AUTOSAR XML (schema 4-3-0)
standard types defined: boolean, float32, sint32, boolean_CompuMethod, boolean_DataConstr, float32_DataConstr, sint32_DataConstr, uint8, sint16, uint16
package /ASP_DataTypes
  8 x impl type:
    As_FeatureOutput: category=STRUCTURE
      element Status: implementation-data-type=As_Status  # Information if feature is available
      element Available: implementation-data-type=As_SideAvailable  # Feature side dependent availability
      element WarningSide: implementation-data-type=As_Side  # Trigger warning for the feature
    As_FrontWheelRequest: category=STRUCTURE
      6 x element, all with category=TYPE_REFERENCE, implementation-data-type=float32:
        Angle  # Wheel angle request
        AngleRateLimit  # The front wheel angle rate limit
        LowerTorqueLimit  # Minimum value for function applied torque, defined at the steering column
        UpperLorqueLimit  # Maximum value for function applied torque, defined at the steering column
        AdditionalTorque  # The signal can be interpreted as a feed forward signal
        BandwidthScaling  # The desired bandwidth for the angle controller ranges from 0 (minimum bandwidth) to 1 (maximum bandwidth)
    As_LateralControlMode: compu {0=As_NoRequest, 1=As_TrafficAssist, 2=As_Lka, 3=As_ElkaRoadEdge, 4=As_ElkaFrontObjects, 5=As_ElkaBlis}, implementation-data-type=sint32
    As_LateralControlOutput: category=STRUCTURE
      element Mode: implementation-data-type=As_LateralControlMode  # Requested lateral actuation mode
      element FrontWheelRequest: implementation-data-type=As_FrontWheelRequest  # Requested front wheel actuation
    As_LssOutput: category=STRUCTURE
      6 x element, all with category=TYPE_REFERENCE:
        Ldw: implementation-data-type=As_FeatureOutput  # Feature output for LDW function
        Lka: implementation-data-type=As_FeatureOutput  # Feature output for LKA function
        ElkaRoadEdge: implementation-data-type=As_FeatureOutput  # Feature output for eLKA Road Edge function
        ElkaFrontObjects: implementation-data-type=As_FeatureOutput  # Feature output for eLKA Front Objects function (e.g. oncoming)
        ElkaRearObjects: implementation-data-type=As_FeatureOutput  # Feature output for eLKA Rear Objects function (e.g. Blind Spot)
        RequestPostEventMessage: implementation-data-type=boolean  # Post event message request
    As_Side: compu {0=As_None, 1=As_Left, 2=As_Right, 3=As_LeftAndRight}, implementation-data-type=sint32
    As_SideAvailable: category=STRUCTURE
      element Left: implementation-data-type=boolean  # Available left side
      element Right: implementation-data-type=boolean  # Available right side
    As_Status: compu {0=As_Disabled, 1=As_Unavailable, 2=As_Available}, implementation-data-type=sint32
package /ASP_PortInterfaces
  sender receiver interface LateralControlOutputInterface: invalidation-policy{data-element=LateralControlOutputInterface/Element, handle-invalid=DONT-INVALIDATE}
    data Element: type=As_LateralControlOutput
  sender receiver interface LssOutputInterface: invalidation-policy{data-element=LssOutputInterface/Element, handle-invalid=DONT-INVALIDATE}
    data Element: type=As_LssOutput
package /ComponentTypes/HkmcComponent/HkmcLkaLdwAdap
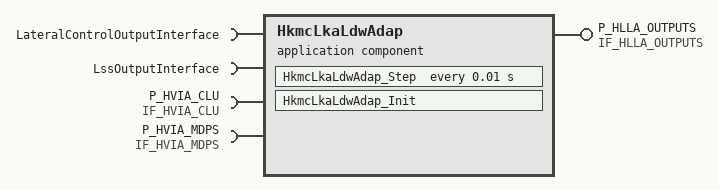
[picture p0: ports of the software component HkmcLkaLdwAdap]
  application sw component type HkmcLkaLdwAdap
    provide port P_HLLA_OUTPUTS: nonqueued-sender-com-spec{data-element=DE_HLLA_OUTPUTS, init-value=fields=[LkaAdap_OptUsmSta:0, LkaAdap_ToiFltSta:0, LkaAdap_ActToiSta:0, LkaAdap_StrTrqReqVal:0, LkaAdap_RHLnWrnSta:0, LkaAdap_LHLnWrnSta:0, LkaAdap_SysWrn:0, LkaAdap_RcgSta:0, LkaAdap_HndsoffSnd:0, LkaAdap_UsmMod:0, LkaAdap_SysIndReq:0, LkaAdap_leftLaneLateral_distance:0, LkaAdap_rightLaneLateral_distance:0, LkaAdap_leftLaneheading:0, LkaAdap_rightLaneheading:0, LkaAdap_leftLanecurvature:0, LkaAdap_leftLanecurvature_rate:0, LkaAdap_rightLanecurvature_rate:0, LkaAdap_leftLaneDetection_distance:0, LkaAdap_rightLaneDetection_distance:0, LkaAdap_lane_right_color:0, LkaAdap_lane_left_color:0, LkaAdap_leftLanemeasurement_quality:0, LkaAdap_rightLanemeasurement_quality:0, LkaAdap_leftLanemarkingtype:0, LkaAdap_rightLanemarkingtype:0, LkaAdap_neighborleftLaneLateral_distance:0, LkaAdap_neighborrightLaneLateral_distance:0, LkaAdap_neighborleftLaneheading:0, LkaAdap_neighborrightLaneheading:0, LkaAdap_neighborleftLanecurvature:0, LkaAdap_neighborrightLanecurvature:0, LkaAdap_neighborleftLanecurvature_rate:0, LkaAdap_neighborrightLanecurvature_rate:0, LkaAdap_neighborleftmeasurement_quality:0, LkaAdap_neighborrightmeasurement_quality:0, LkaAdap_neighborleftLanemarkingtype:0, LkaAdap_neighborrightLanemarkingtype:0]}, provided-interface=IF_HLLA_OUTPUTS
    4 x require port:
      LateralControlOutputInterface: nonqueued-receiver-com-spec{data-element=LateralControlOutputInterface/Element, filter=data-filter-type=ALWAYS}, required-interface=LateralControlOutputInterface
      LssOutputInterface: nonqueued-receiver-com-spec{data-element=LssOutputInterface/Element, filter=data-filter-type=ALWAYS}, required-interface=LssOutputInterface
      P_HVIA_CLU: nonqueued-receiver-com-spec{data-element=DE_HVIA_CLU, filter=data-filter-type=ALWAYS, init-value=fields=[HkmcVehicleInput_SpdUnitTyp:0, HkmcVehicleInput_Fca1stWrngSetReq:0, HkmcVehicleInput_AdasFCASetReq:0, HkmcVehicleInput_LkaModSetReq:0, HkmcVehInput_HBA_NValueSet:0, HkmcVehicleInput_AdasISLASetReq:0]}, required-interface=IF_HVIA_CLU
      P_HVIA_MDPS: nonqueued-receiver-com-spec{data-element=DE_HVIA_MDPS, filter=data-filter-type=ALWAYS, init-value=fields=HkmcVehicleInput_LkaToiUnblSta:0}, required-interface=IF_HVIA_MDPS
    behavior HkmcLkaLdwAdap_InternalBehavior
      init event HkmcLkaLdwAdap_InitEvent: start-on-event=HkmcLkaLdwAdap_Init
      timing event HkmcLkaLdwAdap_Step_TE: start-on-event=HkmcLkaLdwAdap_Step, period=0.01
      runnable HkmcLkaLdwAdap_Init
        data-receive-point-by-arguments:
          4 x access:
            REC_LateralControlOutputInterface_Element: accessed-variable=LateralControlOutputInterface.Element
            REC_LssOutputInterface_Element: accessed-variable=LssOutputInterface.Element
            REC_P_HVIA_CLU_DE_HVIA_CLU: accessed-variable=P_HVIA_CLU.DE_HVIA_CLU
            REC_P_HVIA_MDPS_DE_HVIA_MDPS: accessed-variable=P_HVIA_MDPS.DE_HVIA_MDPS
        data-send-points:
          access SEND_P_HLLA_OUTPUTS_DE_HLLA_OUTPUTS: accessed-variable=P_HLLA_OUTPUTS.DE_HLLA_OUTPUTS
      runnable HkmcLkaLdwAdap_Step
        data-receive-point-by-arguments:
          4 x access:
            REC_LateralControlOutputInterface_Element: accessed-variable=LateralControlOutputInterface.Element
            REC_LssOutputInterface_Element: accessed-variable=LssOutputInterface.Element
            REC_P_HVIA_CLU_DE_HVIA_CLU: accessed-variable=P_HVIA_CLU.DE_HVIA_CLU
            REC_P_HVIA_MDPS_DE_HVIA_MDPS: accessed-variable=P_HVIA_MDPS.DE_HVIA_MDPS
        data-send-points:
          access SEND_P_HLLA_OUTPUTS_DE_HLLA_OUTPUTS: accessed-variable=P_HLLA_OUTPUTS.DE_HLLA_OUTPUTS
  swc implementation HkmcLkaLdwAdap_Implementation: behavior=HkmcLkaLdwAdap_InternalBehavior
    code-descriptors:
      code Default: artifact-descriptors=autosar-engineering-object={short-label=Default, category=SWSRC}
package /ComponentTypes/HkmcComponent/HkmcLkaLdwAdap/DataTypes
  39 x impl type, all with sw-calibration-access=READ-ONLY, type-emitter=RTE:
    HLLA_OUTPUTS_T: category=STRUCTURE
      38 x element, all with category=TYPE_REFERENCE:
        LkaAdap_OptUsmSta: implementation-data-type=LkaAdap_OptUsmSta
        LkaAdap_ToiFltSta: implementation-data-type=LkaAdap_ToiFltSta
        LkaAdap_ActToiSta: implementation-data-type=LkaAdap_ActToiSta
        LkaAdap_StrTrqReqVal: implementation-data-type=LkaAdap_StrTrqReqVal
        LkaAdap_RHLnWrnSta: implementation-data-type=LkaAdap_RHLnWrnSta
        LkaAdap_LHLnWrnSta: implementation-data-type=LkaAdap_LHLnWrnSta
        LkaAdap_SysWrn: implementation-data-type=LkaAdap_SysWrn
        LkaAdap_RcgSta: implementation-data-type=LkaAdap_RcgSta
        LkaAdap_HndsoffSnd: implementation-data-type=LkaAdap_HndsoffSnd
        LkaAdap_UsmMod: implementation-data-type=LkaAdap_UsmMod
        LkaAdap_SysIndReq: implementation-data-type=LkaAdap_SysIndReq
        LkaAdap_leftLaneLateral_distance: implementation-data-type=LkaAdap_leftLaneLateral_distance
        LkaAdap_rightLaneLateral_distance: implementation-data-type=LkaAdap_rightLaneLateral_distance
        LkaAdap_leftLaneheading: implementation-data-type=LkaAdap_leftLaneheading
        LkaAdap_rightLaneheading: implementation-data-type=LkaAdap_rightLaneheading
        LkaAdap_leftLanecurvature: implementation-data-type=LkaAdap_leftLanecurvature
        LkaAdap_leftLanecurvature_rate: implementation-data-type=LkaAdap_leftLanecurvature_rate
        LkaAdap_rightLanecurvature_rate: implementation-data-type=LkaAdap_rightLanecurvature_rate
        LkaAdap_leftLaneDetection_distance: implementation-data-type=LkaAdap_leftLaneDetection_distance
        LkaAdap_rightLaneDetection_distance: implementation-data-type=LkaAdap_rightLaneDetection_distance
        LkaAdap_lane_right_color: implementation-data-type=LkaAdap_lane_right_color
        LkaAdap_lane_left_color: implementation-data-type=LkaAdap_lane_left_color
        LkaAdap_leftLanemeasurement_quality: implementation-data-type=LkaAdap_leftLanemeasurement_quality
        LkaAdap_rightLanemeasurement_quality: implementation-data-type=LkaAdap_rightLanemeasurement_quality
        LkaAdap_leftLanemarkingtype: implementation-data-type=LkaAdap_leftLanemarkingtype
        LkaAdap_rightLanemarkingtype: implementation-data-type=LkaAdap_rightLanemarkingtype
        LkaAdap_neighborleftLaneLateral_distance: implementation-data-type=LkaAdap_neighborleftLaneLateral_distance
        LkaAdap_neighborrightLaneLateral_distance: implementation-data-type=LkaAdap_neighborrightLaneLateral_distance
        LkaAdap_neighborleftLaneheading: implementation-data-type=LkaAdap_neighborleftLaneheading
        LkaAdap_neighborrightLaneheading: implementation-data-type=LkaAdap_neighborrightLaneheading
        LkaAdap_neighborleftLanecurvature: implementation-data-type=LkaAdap_neighborleftLanecurvature
        LkaAdap_neighborrightLanecurvature: implementation-data-type=LkaAdap_neighborrightLanecurvature
        LkaAdap_neighborleftLanecurvature_rate: implementation-data-type=LkaAdap_neighborleftLanecurvature_rate
        LkaAdap_neighborrightLanecurvature_rate: implementation-data-type=LkaAdap_neighborrightLanecurvature_rate
        LkaAdap_neighborleftmeasurement_quality: implementation-data-type=LkaAdap_neighborleftmeasurement_quality
        LkaAdap_neighborrightmeasurement_quality: implementation-data-type=LkaAdap_neighborrightmeasurement_quality
        LkaAdap_neighborleftLanemarkingtype: implementation-data-type=LkaAdap_neighborleftLanemarkingtype
        LkaAdap_neighborrightLanemarkingtype: implementation-data-type=LkaAdap_neighborrightLanemarkingtype
    LkaAdap_ActToiSta: category=VALUE, base-type=DataType/uint8, compu {0=Cx0_ActTS_Deactivate_TOI, 1=Cx1_ActTS_Activate_TOI, 2=Cx2_ActTS_Reserved, 3=Cx3_ActTS_Error_indicator}
    LkaAdap_HndsoffSnd: category=VALUE, base-type=DataType/uint8, compu {0=Cx0_HndsoffS_Off, 1=Cx1_HndsoffS_Handsoff_Sound_Warning, 2=Cx2_HndsoffS_Reserved, 3=Cx3_HndsoffS_Reserved}
    LkaAdap_lane_left_color: category=VALUE, base-type=BaseTypes/uint8, compu {0=Cx0_LkaLaneL_Color_Unknown, 1=Cx1_LkaLaneL_Color_White, 2=Cx2_LkaLaneL_Color_YellowOrangeRed, 3=Cx3_LkaLaneL_Color_BlueGreen}
    LkaAdap_lane_right_color: category=VALUE, base-type=DataType/uint8, compu {0=Cx0_LkaLaneR_Color_Unknown, 1=Cx1_LkaLaneR_Color_White, 2=Cx2_LkaLaneR_Color_YellowOrangeRed, 3=Cx3_LkaLaneR_Color_BlueGreen}
    LkaAdap_leftLanecurvature: category=VALUE, base-type=sint16
    LkaAdap_leftLanecurvature_rate: category=VALUE, base-type=sint16
    LkaAdap_leftLaneDetection_distance: category=VALUE, base-type=uint16
    LkaAdap_leftLaneheading: category=VALUE, base-type=sint16
    LkaAdap_leftLaneLateral_distance: category=VALUE, base-type=sint16
    LkaAdap_leftLanemarkingtype: category=VALUE, base-type=DataType/uint8, compu {0=Cx0_LkaMarkingTypeL_Dashed, 1=Cx1_LkaMarkingTypeL_Solid, 2=Cx2_LkaMarkingTypeL_Undecided, 3=Cx3_LkaMarkingTypeL_RoadEdge, 4=Cx4_LkaMarkingTypeL_DLMInnerSolid, 5=Cx5_LkaMarkingTypeL_DLMInnerDashed, 6=Cx6_LkaMarkingTypeL_DLMInnerUndecided, 7=Cx7_LkaMarkingTypeL_BottsDots, 8=Cx8_LkaMarkingTypeL_Barrier}
    LkaAdap_leftLanemeasurement_quality: category=VALUE, base-type=DataType/uint8, compu {0=Cx0_LkaLaneL_MQ_VeryLowQuality1, 1=Cx1_LkaLaneL_MQ_LowQuality2, 2=Cx2_LkaLaneL_MQ_Prediction, 3=Cx3_LkaLaneL_MQ_HighQuality, 7=Cx7_LkaLaneL_MQ_ErrorIndicator}
    LkaAdap_LHLnWrnSta: category=VALUE, base-type=DataType/uint8, compu {0=Cx0_LHLnWS_No_Warning, 1=Cx1_LHLnWS_HAPTIC_Warning_and_Display, 2=Cx2_LHLnWS_Acoustic_Warning_and_Display, 3=Cx3_LHLnWS_Lane_Departure_Warning, 4=Cx4_LHLnWS_Reserved, 5=Cx5_LHLnWS_Reserved}
    LkaAdap_neighborleftLanecurvature: category=VALUE, base-type=sint16
    LkaAdap_neighborleftLanecurvature_rate: category=VALUE, base-type=sint16
    LkaAdap_neighborleftLaneheading: category=VALUE, base-type=sint16
    LkaAdap_neighborleftLaneLateral_distance: category=VALUE, base-type=sint16
    LkaAdap_neighborleftLanemarkingtype: category=VALUE, base-type=DataType/uint8, compu {0=Cx0_LkaNMarkingTypeL_Dashed, 1=Cx1_LkaNMarkingTypeL_Solid, 2=Cx2_LkaNMarkingTypeL_Undecided, 3=Cx3_LkaNMarkingTypeL_RoadEdge, 4=Cx4_LkaNMarkingTypeL_DLMInnerSolid, 5=Cx5_LkaNMarkingTypeL_DLMInnerDashed, 6=Cx6_LkaNMarkingTypeL_DLMInnerUndecided, 7=Cx7_LkaNMarkingTypeL_BottsDots, 8=Cx8_LkaNMarkingTypeL_Barrier}
    LkaAdap_neighborleftmeasurement_quality: category=VALUE, base-type=DataType/uint8, compu {0=Cx0_LkaLaneL_MQ_VeryLowQuality1, 1=Cx1_LkaLaneL_MQ_LowQuality2, 2=Cx2_LkaLaneL_MQ_Prediction, 3=Cx3_LkaLaneL_MQ_HighQuality, 7=Cx7_LkaLaneL_MQ_ErrorIndicator}
    LkaAdap_neighborrightLanecurvature: category=VALUE, base-type=sint16
    LkaAdap_neighborrightLanecurvature_rate: category=VALUE, base-type=sint16
    LkaAdap_neighborrightLaneheading: category=VALUE, base-type=sint16
    LkaAdap_neighborrightLaneLateral_distance: category=VALUE, base-type=sint16
    LkaAdap_neighborrightLanemarkingtype: category=VALUE, base-type=DataType/uint8, compu {0=Cx0_LkaNMarkingTypeR_Dashed, 1=Cx1_LkaNMarkingTypeR_Solid, 2=Cx2_LkaNMarkingTypeR_Undecided, 3=Cx3_LkaNMarkingTypeR_RoadEdge, 4=Cx4_LkaNMarkingTypeR_DLMInnerSolid, 5=Cx5_LkaNMarkingTypeR_DLMInnerDashed, 6=Cx6_LkaNMarkingTypeR_DLMInnerUndecided, 7=Cx7_LkaNMarkingTypeR_BottsDots, 8=Cx8_LkaNMarkingTypeR_Barrier}
    LkaAdap_neighborrightmeasurement_quality: category=VALUE, base-type=DataType/uint8, compu {0=Cx0_LkaLaneR_MQ_VeryLowQuality1, 1=Cx1_LkaLaneR_MQ_LowQuality2, 2=Cx2_LkaLaneR_MQ_Prediction, 3=Cx3_LkaLaneR_MQ_HighQuality, 7=Cx7_LkaLaneR_MQ_ErrorIndicator}
    LkaAdap_OptUsmSta: category=VALUE, base-type=DataType/uint8, compu {0=Cx0_OptUS_None_LKA_LDW_Option_Default, 1=Cx1_OptUS_LDW, 2=Cx2_OptUS_LKA, 3=Cx3_OptUS_ACTIVE_LKA, 4=Cx4_OptUS_LDW_Only, 5=Cx5_OptUS_LDW_only_OFF, 6=Cx6_OptUS_LDW_LKA_OFF, 7=Cx7_OptUS_Invalid, 8=Cx8_OptUS_Reserved}
    LkaAdap_RcgSta: category=VALUE, base-type=DataType/uint8, compu {0=Cx0_RcgS_Not_Recognized, 1=Cx1_RcgS_Left_Lane_Recognized, 2=Cx2_RcgS_Right_Lane_Recognized, 3=Cx3_RcgS_Full_Lane_Recognized, 4=Cx4_RcgS_Reserved, 5=Cx5_RcgS_Reserved, 6=Cx6_RcgS_Reserved, 7=Cx7_RcgS_Reserved}
    LkaAdap_RHLnWrnSta: category=VALUE, base-type=DataType/uint8, compu {0=Cx0_RHLnWS_No_Warning, 1=Cx1_RHLnWS_HAPTIC_Warning_and_Display, 2=Cx2_RHLnWS_Acoustic_Warning_and_Display, 3=Cx3_RHLnWS_Lane_Departure_Warning, 4=Cx4_RHLnWS_Reserved, 5=Cx5_RHLnWS_Reserved}
    LkaAdap_rightLanecurvature_rate: category=VALUE, base-type=sint16
    LkaAdap_rightLaneDetection_distance: category=VALUE, base-type=uint16
    LkaAdap_rightLaneheading: category=VALUE, base-type=sint16
    LkaAdap_rightLaneLateral_distance: category=VALUE, base-type=sint16
    LkaAdap_rightLanemarkingtype: category=VALUE, base-type=DataType/uint8, compu {0=Cx0_LkaMarkingTypeR_Dashed, 1=Cx1_LkaMarkingTypeR_Solid, 2=Cx2_LkaMarkingTypeR_Undecided, 3=Cx3_LkaMarkingTypeR_RoadEdge, 4=Cx4_LkaMarkingTypeR_DLMInnerSolid, 5=Cx5_LkaMarkingTypeR_DLMInnerDashed, 6=Cx6_LkaMarkingTypeR_DLMInnerUndecided, 7=Cx7_LkaMarkingTypeR_BottsDots, 8=Cx8_LkaMarkingTypeR_Barrier}
    LkaAdap_rightLanemeasurement_quality: category=VALUE, base-type=DataType/uint8, compu {0=Cx0_LkaLaneR_MQ_VeryLowQuality1, 1=Cx1_LkaLaneR_MQ_LowQuality2, 2=Cx2_LkaLaneR_MQ_Prediction, 3=Cx3_LkaLaneR_MQ_HighQuality, 7=Cx7_LkaLaneR_MQ_ErrorIndicator}
    LkaAdap_StrTrqReqVal: category=VALUE, base-type=DataType/uint8, compu {0=In_analysis}
    LkaAdap_SysIndReq: category=VALUE, base-type=DataType/uint8, compu {0=Cx0_SysIR_Off, 1=Cx1_SysIR_White_On, 2=Cx2_SysIR_Lane_Recognized_Green_On, 3=Cx3_SysIR_Lane_Departure_Green_Blink, 4=Cx4_SysIR_System_Fail_Orange_On, 5=Cx5_SysIR_Not_Calibrated_Orange_Blink, 6=Cx6_SysIR_Regulation_Orange_On, 7=Cx7_SysIR_White_Blink, 8=Cx8_SysIR_Unavailable_Gray_On, 9=Cx9_SysIR_Reserved}
    LkaAdap_SysWrn:
      category=VALUE
      base-type=DataType/uint8
      compu {0=Cx0_SysW_No_Info, 1=Cx1_SysW_Reserved, 2=Cx2_SysW_Reserved, 3=Cx3_SysW_Reserved, 4=Cx4_SysW_HandsOff_Warning_1, 5=Cx5_SysW_HandsOff_Warning_2, 6=Cx6_SysW_HandsOff_Warning_3, 7=Cx7_SysW_Reserved, 8=Cx8_SysW_Reserved, 9=Cx9_SysW_System_Automatic_off, 10=CxA_SysW_Reserved, 11=CxB_SysW_Reserved, 12=CxC_SysW_Reserved, 13=CxD_SysW_Reserved, 14=CxE_SysW_Reserved, 15=CxF_SysW_System_Fail}
    LkaAdap_ToiFltSta: category=VALUE, base-type=DataType/uint8, compu {0=Cx0_ToiFS_No_Fault, 1=Cx1_ToiFS_Fault_Present, 2=Cx2_ToiFS_Reserved, 3=Cx3_ToiFS_Error_indicatorr}
    LkaAdap_UsmMod: category=VALUE, base-type=DataType/uint8, compu {0=Cx0_UsmM_NONE, 1=Cx1_UsmM_LKA_1_Mode, 2=Cx2_UsmM_LKA_2_Mode, 3=Cx3_UsmM_LDW, 4=Cx4_Reserved}
package /ComponentTypes/HkmcComponent/HkmcLkaLdwAdap/PortInterfaces
  sender receiver interface IF_HLLA_OUTPUTS: invalidation-policy{data-element=DE_HLLA_OUTPUTS, handle-invalid=DONT-INVALIDATE}
    data DE_HLLA_OUTPUTS: type=HLLA_OUTPUTS_T
package /ComponentTypes/HkmcComponent/HkmcVehicleInputAdap/DataTypes
  9 x impl type, all with sw-calibration-access=READ-ONLY, type-emitter=RTE:
    HkmcVehicleInput_AdasFCASetReq: category=VALUE, base-type=DataType/uint8, compu {0=Cx0_AdasFCASR_Default, 1=Cx1_AdasFCASR_Off, 2=Cx2_AdasFCASR_Warning, 3=Cx3_AdasFCASR_Assist, 4=Cx4_AdasFCASR_Reserved, 5=Cx5_AdasFCASR_Reserved, 6=Cx6_AdasFCASR_Reserved, 7=Cx7_AdasFCASR_Invalid}
    HkmcVehicleInput_AdasISLASetReq: category=VALUE, base-type=DataType/uint8, compu {0=Cx0_AdasSetReq_Default, 1=Cx1_AdasSetReq_Off, 2=Cx2_AdasSetReq_ISLW, 3=Cx3_AdasSetReq_ISLA, 4=Cx4_AdasSetReq_Reserved, 5=Cx5_AdasSetReq_Reserved, 6=Cx6_AdasSetReq_Reserved, 7=Cx7_AdasSetReq_Invalid}
    HkmcVehicleInput_Fca1stWrngSetReq: category=VALUE, base-type=DataType/uint8, compu {0=Cx0_Fca1stWSR_Default, 1=Cx1_Fca1stWSR_Late, 2=Cx2_Fca1stWSR_Normal, 3=Cx3_Fca1stWSR_Early, 4=Cx4_Fca1stWSR_Reserved, 5=Cx5_Fca1stWSR_Reserved, 6=Cx6_Fca1stWSR_Reserved, 7=Cx7_Fca1stWSR_Invalid, 8=Cx8_Fca1stWSR_Reserved, 9=Cx9_Fca1stWSR_Reserved, 16=Cx10_Fca1stWSR_Reserved, 17=Cx11_Fca1stWSR_Reserved}
    HkmcVehicleInput_LkaModSetReq: category=VALUE, base-type=DataType/uint8, compu {0=Cx0_LkaModSR_Default, 1=Cx1_LkaModSR_LDW_mode, 2=Cx2_LkaModSR_LKA_mode, 3=Cx3_LkaModSR_Reserved, 4=Cx4_LkaModSR_LDW_ON, 5=Cx5_LkaModSR_LDW_OFF, 6=Cx6_LkaModSR_LDW_LKA_OFF, 7=Cx7_LkaModSR_Invalid}
    HkmcVehicleInput_LkaToiUnblSta: category=VALUE, base-type=DataType/uint8, compu {0=Cx0_LkaTUS_Available, 1=Cx1_LkaTUS_Unavailable, 2=Cx2_LkaTUS_Not_Used, 3=Cx3_LkaTUS_Error_Indicator}
    HkmcVehicleInput_SpdUnitTyp: category=VALUE, base-type=DataType/uint8, compu {0=Cx0_SpdUT_kmperh, 1=Cx1_SpdUT_MPH, 2=Cx2_SpdUT_Not_used, 3=Cx3_SpdUT_Error_Indicator}
    HkmcVehInput_HBA_NValueSet: category=VALUE, base-type=DataType/uint8, compu {0=Cx0_NVS_Default, 1=Cx1_NVS_HBA_Function_Off, 2=Cx2_NVS_HBA_Funtion_On, 3=Cx3_NVS_Invalid}
    HVIA_CLU_T: category=STRUCTURE
      6 x element, all with category=TYPE_REFERENCE:
        HkmcVehicleInput_SpdUnitTyp: implementation-data-type=HkmcVehicleInput_SpdUnitTyp
        HkmcVehicleInput_Fca1stWrngSetReq: implementation-data-type=HkmcVehicleInput_Fca1stWrngSetReq
        HkmcVehicleInput_AdasFCASetReq: implementation-data-type=HkmcVehicleInput_AdasFCASetReq
        HkmcVehicleInput_LkaModSetReq: implementation-data-type=HkmcVehicleInput_LkaModSetReq
        HkmcVehInput_HBA_NValueSet: implementation-data-type=HkmcVehInput_HBA_NValueSet
        HkmcVehicleInput_AdasISLASetReq: implementation-data-type=HkmcVehicleInput_AdasISLASetReq
    HVIA_MDPS_T: category=STRUCTURE
      element HkmcVehicleInput_LkaToiUnblSta: implementation-data-type=HkmcVehicleInput_LkaToiUnblSta
package /ComponentTypes/HkmcComponent/HkmcVehicleInputAdap/PortInterfaces
  sender receiver interface IF_HVIA_CLU: invalidation-policy{data-element=DE_HVIA_CLU, handle-invalid=DONT-INVALIDATE}
    data DE_HVIA_CLU: type=HVIA_CLU_T
  sender receiver interface IF_HVIA_MDPS: invalidation-policy{data-element=DE_HVIA_MDPS, handle-invalid=DONT-INVALIDATE}
    data DE_HVIA_MDPS: type=HVIA_MDPS_T
